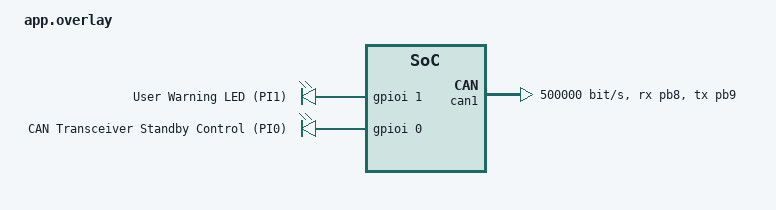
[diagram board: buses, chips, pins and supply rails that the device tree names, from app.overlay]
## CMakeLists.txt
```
# ==============================================================================
# File: zephyr_project/CMakeLists.txt
# Mục đích: File điều phối biên dịch chuẩn của ứng dụng Zephyr RTOS
# ==============================================================================

cmake_minimum_required(VERSION 3.20.0)

# Tìm kiếm và tích hợp hệ điều hành Zephyr RTOS vào dự án
find_package(Zephyr REQUIRED HINTS $ENV{ZEPHYR_BASE})

# Đặt tên định danh cho dự án ô tô
project(automotive_can_gateway_cluster)

# Đăng ký các file mã nguồn C vào target biên dịch
target_sources(app PRIVATE
    src/main.c
    src/can_gateway.c
    src/dbc_decoder.c
    src/safety_monitor.c
    src/diag_shell.c
)
```

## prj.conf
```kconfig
# ==============================================================================
# File: zephyr_project/prj.conf
# Mục đích: Cấu hình tính năng Kconfig cho dự án Automotive CAN Gateway & Cluster
# ==============================================================================

# 1. Bật hệ thống CAN Bus và GPIO điều khiển
CONFIG_CAN=y
CONFIG_CAN_INIT_PRIORITY=80
CONFIG_CAN_MAX_FILTER=5
CONFIG_GPIO=y

# 2. Bật hệ thống Console UART và Ghi Log Bất Đồng Bộ
CONFIG_SERIAL=y
CONFIG_CONSOLE=y
CONFIG_UART_CONSOLE=y
CONFIG_LOG=y
CONFIG_LOG_MODE_DEFERRED=y
CONFIG_LOG_DEFAULT_LEVEL=3

# 3. Khiên bảo vệ tràn ngăn xếp bằng phần cứng MPU Cortex-M7
CONFIG_ARM_MPU=y
CONFIG_HW_STACK_PROTECTION=y
CONFIG_MPU_STACK_GUARD=y

# 4. Giám sát độ đầy Stack và Đặt tên cho các Thread lúc Runtime
CONFIG_THREAD_NAME=y
CONFIG_THREAD_ANALYZER=y
CONFIG_THREAD_ANALYZER_USE_LOG=y
CONFIG_THREAD_ANALYZER_AUTO=y
CONFIG_THREAD_ANALYZER_AUTO_INTERVAL=10

# 5. Giao diện dòng lệnh tương tác chẩn đoán Zephyr Shell CLI
CONFIG_SHELL=y
CONFIG_SHELL_BACKEND_SERIAL=y
CONFIG_SHELL_PROMPT_UART="ecu:~$ "
```

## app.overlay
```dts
/* ==============================================================================
 * File: zephyr_project/app.overlay
 * Mục đích: Ghi đè phần cứng cho bo mạch STM32F746G-Discovery
 * ============================================================================== */

/ {
    aliases {
        can-primary = &can1;
        led-warn = &user_led_1;
    };

    leds {
        compatible = "gpio-leds";
        user_led_1: led_1 {
            gpios = <&gpioi 1 GPIO_ACTIVE_HIGH>;
            label = "User Warning LED (PI1)";
        };
    };

    /* Định nghĩa chân Standby của IC CAN Transceiver ngoài (TJA1050 / SN65HVD230) */
    transceiver {
        compatible = "gpio-leds";
        can_stb: stb_pin {
            gpios = <&gpioi 0 GPIO_ACTIVE_HIGH>;
            label = "CAN Transceiver Standby Control (PI0)";
        };
    };
};

/* Kích hoạt ngoại vi CAN1 (Chân PB8: RX, PB9: TX) */
&can1 {
    pinctrl-0 = <&can1_rx_pb8 &can1_tx_pb9>;
    pinctrl-names = "default";
    status = "okay";
    bitrate = <500000>;
    sample-point = <875>;

    /* Mẹo: Bật thuộc tính 'loopback;' bên dưới nếu muốn tự test trên 1 bo mạch duy nhất */
    /* loopback; */
};
```

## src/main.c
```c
/**
 * ==============================================================================
 * File: zephyr_project/src/main.c
 * Mục đích: Ứng dụng chính Zephyr RTOS (CAN Gateway, DBC/E2E, Multi-threading, Safety Monitor)
 * ==============================================================================
 */

#include <zephyr/kernel.h>
#include <zephyr/drivers/gpio.h>
#include <zephyr/logging/log.h>
#include "can_gateway.h"
#include "dbc_decoder.h"
#include "safety_monitor.h"

LOG_MODULE_REGISTER(main_app, LOG_LEVEL_INF);

/* 1. Biến toàn cục lưu trữ thông số xe hơi, được bảo vệ bằng k_mutex (Priority Inheritance) */
VehicleTelemetry_t g_current_telemetry = { 0 };
K_MUTEX_DEFINE(g_telemetry_mutex);

/* 2. Lấy đèn LED cảnh báo người dùng từ Devicetree (Chân PI1) */
static const struct gpio_dt_spec warn_led = GPIO_DT_SPEC_GET_OR(DT_ALIAS(led_warn), gpios, {0});

/* ==============================================================================
 * LUỒNG 1: CAN INGESTION & DBC DECODER WORKER (Mức ưu tiên 5)
 * ============================================================================== */
#define CAN_WORKER_STACK_SIZE 2048
#define CAN_WORKER_PRIO       5

void can_worker_thread_entry(void *p1, void *p2, void *p3)
{
    ARG_UNUSED(p1); ARG_UNUSED(p2); ARG_UNUSED(p3);

    struct can_frame rx_frame;
    VehicleTelemetry_t local_tel;

    LOG_INF("CAN Worker Thread da khoi dong (Priority = %d).", CAN_WORKER_PRIO);

    while (1) {
        /* Chờ gói tin CAN mới từ hàng đợi (Zero-CPU khi bus rảnh) */
        k_msgq_get(&raw_can_msgq, &rx_frame, K_FOREVER);

        /* Giải mã Vector DBC và xác thực 3 lớp an toàn AUTOSAR E2E */
        if (dbc_decode_vehicle_frame(rx_frame.data, rx_frame.dlc, &local_tel)) {
            /* Cập nhật thông số an toàn đa luồng bằng Mutex */
            k_mutex_lock(&g_telemetry_mutex, K_FOREVER);
            g_current_telemetry = local_tel;
            k_mutex_unlock(&g_telemetry_mutex);

            /* Gửi cập nhật sang hệ thống giám sát sự cố */
            safety_monitor_update(&local_tel);

            LOG_INF("CAN Packet OK: Speed = %u km/h | RPM = %u | Temp = %d C",
                    local_tel.speed_kmh, local_tel.engine_rpm, local_tel.coolant_temp);
        } else {
            LOG_WRN("CAN Frame ID 0x%03X bi loi E2E hoac khong dung dinh dang!", rx_frame.id);
        }
    }
}

K_THREAD_DEFINE(can_worker_tid, CAN_WORKER_STACK_SIZE,
                can_worker_thread_entry, NULL, NULL, NULL,
                CAN_WORKER_PRIO, 0, 0);

/* ==============================================================================
 * LUỒNG 2: SAFETY SUPERVISOR & LED ALERT (Mức ưu tiên 6)
 * ============================================================================== */
#define SAFETY_STACK_SIZE 1024
#define SAFETY_PRIO       6

void safety_thread_entry(void *p1, void *p2, void *p3)
{
    ARG_UNUSED(p1); ARG_UNUSED(p2); ARG_UNUSED(p3);

    if (warn_led.port != NULL && gpio_is_ready_dt(&warn_led)) {
        gpio_pin_configure_dt(&warn_led, GPIO_OUTPUT_INACTIVE);
    }

    LOG_INF("Safety Supervisor Thread da khoi dong (Priority = %d).", SAFETY_PRIO);

    while (1) {
        /* Kiểm tra định kỳ mỗi 200ms */
        k_msleep(200);

        if (safety_monitor_is_fault_active()) {
            /* Nếu có lỗi phát sinh (Timeout mất CAN, Quá nhiệt...) -> Nhấp nháy LED cảnh báo */
            if (warn_led.port != NULL) {
                gpio_pin_toggle_dt(&warn_led);
            }
        } else {
            /* Hệ thống bình thường: Tắt đèn LED */
            if (warn_led.port != NULL) {
                gpio_pin_set_dt(&warn_led, 0);
            }
        }
    }
}

K_THREAD_DEFINE(safety_tid, SAFETY_STACK_SIZE,
                safety_thread_entry, NULL, NULL, NULL,
                SAFETY_PRIO, 0, 0);

/* ==============================================================================
 * LUỒNG CHÍNH (MAIN THREAD)
 * ============================================================================== */
int main(void)
{
    LOG_INF("==================================================");
    LOG_INF("   AUTOMOTIVE SMART CAN GATEWAY & CLUSTER OK!     ");
    LOG_INF("   RTOS Kernel: Zephyr OS on STM32F746 Cortex-M7  ");
    LOG_INF("   Build Time: %s %s", __DATE__, __TIME__);
    LOG_INF("==================================================");

    /* 1. Khởi tạo hệ thống giám sát an toàn */
    safety_monitor_init();

    /* 2. Khởi tạo CAN Subsystem và cấu hình bộ lọc */
    int ret = can_gateway_init();
    if (ret != 0) {
        LOG_ERR("Loi khoi tao CAN Gateway! Ma loi: %d", ret);
        return ret;
    }

    LOG_INF("Go lenh 'help' tren Console UART de xem danh sach lenh chan doan CLI.");
    return 0;
}
```

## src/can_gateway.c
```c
/**
 * ==============================================================================
 * File: zephyr_project/src/can_gateway.c
 * Mục đích: Hiện thực hóa giao tiếp CAN Subsystem, STB Pin và Bus-Off FSM
 * ==============================================================================
 */

#include "can_gateway.h"
#include <zephyr/drivers/gpio.h>
#include <zephyr/logging/log.h>

LOG_MODULE_REGISTER(can_gateway, LOG_LEVEL_INF);

/* 1. Định nghĩa hàng đợi chứa tối đa 16 gói tin CAN */
K_MSGQ_DEFINE(raw_can_msgq, sizeof(struct can_frame), CAN_RX_QUEUE_SIZE, 4);

/* 2. Lấy thiết bị CAN từ Devicetree */
static const struct device *const can_dev = DEVICE_DT_GET(DT_ALIAS(can_primary));

/* 3. Lấy chân STB điều khiển IC Transceiver từ Devicetree */
static const struct gpio_dt_spec stb_spec = GPIO_DT_SPEC_GET_OR(DT_NODELABEL(can_stb), gpios, {0});

/* Callback giám sát máy trạng thái lỗi phần cứng Bus-Off */
static void can_state_change_handler(const struct device *dev, enum can_state state,
                                     struct can_bus_err_cnt err_cnt, void *user_data)
{
    ARG_UNUSED(dev);
    ARG_UNUSED(user_data);

    if (state == CAN_STATE_BUS_OFF) {
        LOG_ERR("CAN ALARM: Phat hien trang thai BUS-OFF! TEC=%d, REC=%d", 
                err_cnt.tx_err_cnt, err_cnt.rx_err_cnt);
        /* Kích hoạt tự động phục hồi an toàn */
#if defined(CONFIG_CAN_MANUAL_RECOVERY_MODE)
        can_recover(can_dev, K_MSEC(100));
#else
        /* Trên STM32 bxCAN, phần cứng tự quản lý Bus-Off (ABOM) hoặc phục hồi bằng stop/start */
        can_stop(can_dev);
        k_msleep(100);
        can_start(can_dev);
#endif
    }
}

int can_gateway_init(void)
{
    int ret;

    /* A. Đánh thức Transceiver: Kéo chân STB xuống mức LOW (0V) */
    if (stb_spec.port != NULL && gpio_is_ready_dt(&stb_spec)) {
        gpio_pin_configure_dt(&stb_spec, GPIO_OUTPUT_INACTIVE);
        gpio_pin_set_dt(&stb_spec, 0);
        LOG_INF("CAN Transceiver da thuc tinh (STB = LOW).");
    }

    /* B. Kiểm tra tính sẵn sàng của bộ điều khiển CAN */
    if (!device_is_ready(can_dev)) {
        LOG_ERR("Loi: Ngoai vi CAN1 chua san sang!");
        return -ENODEV;
    }

    /* C. Đăng ký callback giám sát lỗi Bus-Off */
    can_set_state_change_callback(can_dev, can_state_change_handler, NULL);

    /* D. Bật chế độ Loopback để tự truyền/nhận độc lập trên 1 board mà không cần CAN Transceiver ngoài */
    can_set_mode(can_dev, CAN_MODE_LOOPBACK);

    /* E. Bắt đầu kích hoạt bộ điều khiển CAN */
    ret = can_start(can_dev);
    if (ret != 0) {
        LOG_ERR("Khong the khoi dong CAN controller! Ma loi: %d", ret);
        return ret;
    }

    /* E. Cấu hình bộ lọc phần cứng nhận ID 0x123 (Standard ID) */
    const struct can_filter rx_filter = {
        .id = 0x123,
        .mask = 0x7FF, /* So khớp chính xác ID 0x123 */
        .flags = 0
    };

    /* Gắn trực tiếp bộ lọc phần cứng vào hàng đợi k_msgq (Zero-Lock) */
    ret = can_add_rx_filter_msgq(can_dev, &raw_can_msgq, &rx_filter);
    if (ret < 0) {
        LOG_ERR("Loi dang ky can_add_rx_filter_msgq: %d", ret);
        return ret;
    }

    LOG_INF("CAN Gateway da san sang! Filter ID=0x123 da nap thanh cong.");
    return 0;
}

int can_gateway_send_frame(const struct can_frame *frame)
{
    if (!device_is_ready(can_dev)) return -ENODEV;
    return can_send(can_dev, frame, K_MSEC(100), NULL, NULL);
}
```

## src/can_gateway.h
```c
/**
 * ==============================================================================
 * File: zephyr_project/src/can_gateway.h
 * Mục đích: Giao diện tiếp nhận mạng CAN và hàng đợi k_msgq trong Zephyr
 * ==============================================================================
 */

#ifndef CAN_GATEWAY_H
#define CAN_GATEWAY_H

#include <zephyr/kernel.h>
#include <zephyr/drivers/can.h>

#define CAN_RX_QUEUE_SIZE 16

/* Hàng đợi toàn cục trung chuyển gói tin CAN từ driver ngầm sang Worker Thread */
extern struct k_msgq raw_can_msgq;

/**
 * @brief Khởi tạo ngoại vi CAN1, thức tỉnh Transceiver và gắn filter vào k_msgq
 * @return 0 nếu thành công, mã lỗi âm nếu thất bại
 */
int can_gateway_init(void);

/**
 * @brief Bắn một bản tin CAN ra mạng vật lý
 * @param frame Con trỏ gói tin can_frame
 * @return 0 nếu phát thành công
 */
int can_gateway_send_frame(const struct can_frame *frame);

#endif /* CAN_GATEWAY_H */
```

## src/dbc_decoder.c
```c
/**
 * ==============================================================================
 * File: zephyr_project/src/dbc_decoder.c
 * Mục đích: Cài đặt thuật toán kiểm tra AUTOSAR E2E Profile 1 và giải nén bit DBC
 * ==============================================================================
 */

#include "dbc_decoder.h"
#include <zephyr/logging/log.h>

LOG_MODULE_REGISTER(dbc_decoder, LOG_LEVEL_INF);

/* Thuật toán AUTOSAR E2E CRC-8 (Đa thức SAE J1850 0x2F, Init 0xFF, XOR 0xFF) */
static uint8_t compute_e2e_crc8(const uint8_t *data, uint8_t len, uint16_t data_id)
{
    uint8_t crc = 0xFF;

    /* Nhồi Data ID bí mật vào trước */
    uint8_t id_bytes[2] = { (uint8_t)(data_id & 0xFF), (uint8_t)((data_id >> 8) & 0xFF) };
    for (int i = 0; i < 2; i++) {
        crc ^= id_bytes[i];
        for (int b = 0; b < 8; b++) {
            if (crc & 0x80) {
                crc = (crc << 1) ^ 0x2F;
            } else {
                crc <<= 1;
            }
        }
    }

    /* Tính tiếp qua payload từ Byte 1 đến Byte 7 */
    for (uint8_t i = 0; i < len; i++) {
        crc ^= data[i];
        for (int b = 0; b < 8; b++) {
            if (crc & 0x80) {
                crc = (crc << 1) ^ 0x2F;
            } else {
                crc <<= 1;
            }
        }
    }

    return crc ^ 0xFF;
}

bool dbc_decode_vehicle_frame(const uint8_t *data, uint8_t dlc, VehicleTelemetry_t *out)
{
    if (dlc < 8 || out == NULL) return false;

    static uint8_t last_counter = 0xFF;

    /* 1. KIỂM TRA LỚP 1: E2E CRC-8 */
    uint8_t received_crc = data[0];
    uint8_t expected_crc = compute_e2e_crc8(&data[1], 7, VEHICLE_DATA_ID);

    if (received_crc != expected_crc) {
        LOG_WRN("E2E CANH BAO: Sai ma CRC-8! Nhan: 0x%02X, Tinh: 0x%02X", received_crc, expected_crc);
        out->is_e2e_valid = false;
        return false;
    }

    /* 2. KIỂM TRA LỚP 2: ROLLING COUNTER */
    uint8_t current_counter = data[1] & 0x0F;
    if (last_counter != 0xFF) {
        uint8_t next_counter = (last_counter + 1) % 16;
        if (current_counter != next_counter) {
            LOG_WRN("E2E CANH BAO: Sai Rolling Counter! Hien tai: %d, Mong doi: %d", 
                    current_counter, next_counter);
            out->is_e2e_valid = false;
            return false;
        }
    }
    last_counter = current_counter;
    out->rolling_cnt = current_counter;
    out->is_e2e_valid = true;

    /* 3. GIẢI MÃ TÍN HIỆU VECTOR DBC (TOÁN FIXED-POINT KHÔNG DÙNG FLOAT) */
    /* Signal 1: Tốc độ xe (km/h) tại Byte 2 */
    out->speed_kmh = (uint16_t)data[2];

    /* Signal 2: Vòng tua máy RPM (Byte 3 LSB, Byte 4 MSB, Factor = 0.25 -> chia 4) */
    uint16_t raw_rpm = (uint16_t)data[3] | ((uint16_t)data[4] << 8);
    out->engine_rpm = (raw_rpm >> 2);

    /* Signal 3: Nhiệt độ nước làm mát tại Byte 5 (Factor = 1, Offset = -40) */
    out->coolant_temp = (int16_t)data[5] - 40;

    return true;
}
```

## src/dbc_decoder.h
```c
/**
 * ==============================================================================
 * File: zephyr_project/src/dbc_decoder.h
 * Mục đích: Khai báo giao diện giải mã tín hiệu Vector DBC và AUTOSAR E2E
 * ==============================================================================
 */

#ifndef DBC_DECODER_H
#define DBC_DECODER_H

#include <stdint.h>
#include <stdbool.h>

#define VEHICLE_DATA_ID 0x1A2B /* Data ID bí mật của bản tin xe hơi */

typedef struct {
    uint16_t speed_kmh;     /* Tốc độ xe (0 - 240 km/h) */
    uint16_t engine_rpm;    /* Vòng tua động cơ (0 - 8000 RPM) */
    int16_t  coolant_temp;  /* Nhiệt độ nước làm mát (-40 đến +150 degC) */
    uint8_t  rolling_cnt;   /* Bộ đếm vòng E2E */
    bool     is_e2e_valid;  /* Cờ xác thực toàn vẹn dữ liệu */
} VehicleTelemetry_t;

/**
 * @brief Giải mã gói tin CAN 8-byte, kiểm tra mã AUTOSAR E2E CRC-8 và bóc tách tín hiệu
 * @param data Con trỏ dữ liệu 8 bytes
 * @param dlc Độ dài bản tin
 * @param out Con trỏ lưu trữ thông số sau giải mã
 * @return true nếu giải mã và kiểm tra E2E thành công
 */
bool dbc_decode_vehicle_frame(const uint8_t *data, uint8_t dlc, VehicleTelemetry_t *out);

#endif /* DBC_DECODER_H */
```

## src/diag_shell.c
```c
/**
 * ==============================================================================
 * File: zephyr_project/src/diag_shell.c
 * Mục đích: Giao diện dòng lệnh Zephyr Shell CLI phục vụ chẩn đoán kỹ thuật
 * ==============================================================================
 */

#include <zephyr/kernel.h>
#include <zephyr/shell/shell.h>
#include <stdlib.h>
#include "safety_monitor.h"
#include "can_gateway.h"

extern VehicleTelemetry_t g_current_telemetry;
extern struct k_mutex g_telemetry_mutex;

static int cmd_vehicle_status(const struct shell *sh, size_t argc, char **argv)
{
    ARG_UNUSED(argc);
    ARG_UNUSED(argv);

    k_mutex_lock(&g_telemetry_mutex, K_FOREVER);
    shell_print(sh, "========================================");
    shell_print(sh, "   THONG SO VAN HANH XE HOI (TELEMETRY) ");
    shell_print(sh, "========================================");
    shell_print(sh, "• Toc do hien tai : %u km/h", g_current_telemetry.speed_kmh);
    shell_print(sh, "• Vong tua may    : %u RPM", g_current_telemetry.engine_rpm);
    shell_print(sh, "• Nhiet do nuoc   : %d degC", g_current_telemetry.coolant_temp);
    shell_print(sh, "• Rolling Counter : %u", g_current_telemetry.rolling_cnt);
    shell_print(sh, "• E2E Integrity   : %s", g_current_telemetry.is_e2e_valid ? "VALID (OK)" : "CORRUPT (FAIL)");
    shell_print(sh, "========================================");
    k_mutex_unlock(&g_telemetry_mutex);

    return 0;
}

static int cmd_dtc_read(const struct shell *sh, size_t argc, char **argv)
{
    ARG_UNUSED(argc);
    ARG_UNUSED(argv);

    uint16_t dtcs[8];
    uint8_t count = safety_monitor_get_active_dtc(dtcs, 8);

    shell_print(sh, "Danh sach ma loi chan doan (DTC) hien huu (%u loi):", count);
    if (count == 0) {
        shell_print(sh, "➔ Khong co ma loi nao. He thong AN TOAN tuyet doi.");
    } else {
        for (uint8_t i = 0; i < count; i++) {
            shell_print(sh, " [%u] DTC: 0x%04X", i + 1, dtcs[i]);
        }
    }
    return 0;
}

static int cmd_dtc_clear(const struct shell *sh, size_t argc, char **argv)
{
    ARG_UNUSED(argc);
    ARG_UNUSED(argv);

    safety_monitor_clear_dtc();
    shell_print(sh, "➔ Da xoa toan bo ma loi chan doan thanh cong.");
    return 0;
}

/* --------------------------------------------------------------------------
 * BỘ MÔ PHỎNG PHÁT BẢN TIN CAN XE HƠI (CAN SIMULATOR & INJECTOR)
 * -------------------------------------------------------------------------- */
static bool s_auto_sim = true; /* Mặc định bật tự động để có số liệu xe chạy ngay khi nạp */

static void send_sim_frame(uint16_t speed, uint16_t rpm, int8_t temp, bool corrupt_crc)
{
    static uint8_t sim_counter = 0;
    sim_counter = (sim_counter + 1) % 16;

    uint16_t raw_rpm = rpm * 4;
    uint8_t temp_raw = (uint8_t)(temp + 40);

    struct can_frame sim_frame = {
        .id = 0x123,
        .dlc = 8,
        .data = {
            0, /* Byte 0: CRC */
            sim_counter & 0x0F,
            (uint8_t)speed,
            (uint8_t)(raw_rpm & 0xFF),
            (uint8_t)((raw_rpm >> 8) & 0xFF),
            temp_raw,
            0x00, 0x00
        }
    };

    /* Tính E2E CRC-8 cho payload Byte 1 đến Byte 7 */
    uint8_t crc = 0xFF;
    uint8_t id_bytes[2] = { (uint8_t)(VEHICLE_DATA_ID & 0xFF), (uint8_t)((VEHICLE_DATA_ID >> 8) & 0xFF) };
    for (int i = 0; i < 2; i++) {
        crc ^= id_bytes[i];
        for (int b = 0; b < 8; b++) crc = (crc & 0x80) ? ((crc << 1) ^ 0x2F) : (crc << 1);
    }
    for (int i = 1; i < 8; i++) {
        crc ^= sim_frame.data[i];
        for (int b = 0; b < 8; b++) crc = (crc & 0x80) ? ((crc << 1) ^ 0x2F) : (crc << 1);
    }
    sim_frame.data[0] = corrupt_crc ? (crc ^ 0xAA) : (crc ^ 0xFF);

    can_gateway_send_frame(&sim_frame);
}

/* Luồng phát xe chạy tự động 5Hz (Mỗi 200ms) */
static void sim_thread_entry(void *p1, void *p2, void *p3)
{
    ARG_UNUSED(p1); ARG_UNUSED(p2); ARG_UNUSED(p3);
    uint16_t speed = 50;
    int dir = 1;

    while (1) {
        k_msleep(200);
        if (s_auto_sim) {
            speed += dir * 2;
            if (speed >= 115) dir = -1;
            else if (speed <= 45) dir = 1;

            uint16_t rpm = 1200 + speed * 25; /* RPM: 2325 - 4075 RPM */
            send_sim_frame(speed, rpm, 88, false);
        }
    }
}

K_THREAD_DEFINE(sim_tid, 1024, sim_thread_entry, NULL, NULL, NULL, 7, 0, 0);

/* Lệnh giả lập phát tín hiệu xe hơi thủ công */
static int cmd_can_sim(const struct shell *sh, size_t argc, char **argv)
{
    if (argc < 2) {
        shell_print(sh, "Cu phap: can sim <speed_kmh>");
        return -EINVAL;
    }

    uint16_t speed = (uint16_t)atoi(argv[1]);
    uint16_t rpm = 1200 + speed * 25;
    send_sim_frame(speed, rpm, 88, false);
    shell_print(sh, "➔ Da phat 1 goi tin: Toc do = %u km/h, RPM = %u", speed, rpm);
    return 0;
}

/* Bật / tắt luồng tự động phát */
static int cmd_can_auto(const struct shell *sh, size_t argc, char **argv)
{
    if (argc < 2) {
        shell_print(sh, "Trang thai hien tai: %s. Cu phap: can auto <on|off>", s_auto_sim ? "ON (DANG CHAY)" : "OFF (DA DUNG)");
        return 0;
    }

    if (strcmp(argv[1], "on") == 0) {
        s_auto_sim = true;
        shell_print(sh, "➔ Da BAT mo phong CAN tu dong! Xe dang van hanh tren duong.");
    } else if (strcmp(argv[1], "off") == 0) {
        s_auto_sim = false;
        shell_print(sh, "➔ Da TAT mo phong CAN. Mat tin hieu CAN sau 1s se gay loi DTC_U0100!");
    } else {
        shell_print(sh, "Tham so khong hop le! Dung 'can auto on' hoac 'can auto off'");
    }
    return 0;
}

/* Bơm lỗi cố tình để kiểm tra an toàn AUTOSAR */
static int cmd_can_inject(const struct shell *sh, size_t argc, char **argv)
{
    if (argc < 2) {
        shell_print(sh, "Cu phap: can inject <overheat | overspeed | corrupt>");
        return -EINVAL;
    }

    if (strcmp(argv[1], "overheat") == 0) {
        send_sim_frame(90, 3000, 115, false); /* 115 degC > 105 degC -> DTC_P0115 */
        shell_print(sh, "➔ Da bom loi QUA NHIET (115 degC)! Kiem tra bang 'dtc read'");
    } else if (strcmp(argv[1], "overspeed") == 0) {
        send_sim_frame(140, 6800, 88, false); /* 6800 RPM > 6500 RPM -> DTC_P0219 */
        shell_print(sh, "➔ Da bom loi QUA VONG TUA (6800 RPM)! Kiem tra bang 'dtc read'");
    } else if (strcmp(argv[1], "corrupt") == 0) {
        send_sim_frame(80, 2500, 88, true); /* Sai CRC */
        shell_print(sh, "➔ Da bom goi tin SAI MA CRC-8! Kiem tra bang 'vehicle status'");
    } else {
        shell_print(sh, "Loi khong ho tro: overheat, overspeed, corrupt");
    }
    return 0;
}

/* Đăng ký các nhóm lệnh vào Zephyr Shell */
SHELL_STATIC_SUBCMD_SET_CREATE(sub_vehicle,
    SHELL_CMD(status, NULL, "Hien thi thong so xe hoi truc quan", cmd_vehicle_status),
    SHELL_SUBCMD_SET_END
);
SHELL_CMD_REGISTER(vehicle, &sub_vehicle, "Lenh theo doi xe hoi", NULL);

SHELL_STATIC_SUBCMD_SET_CREATE(sub_dtc,
    SHELL_CMD(read, NULL, "Doc danh sach ma loi chan doan", cmd_dtc_read),
    SHELL_CMD(clear, NULL, "Xoa toan bo ma loi chan doan", cmd_dtc_clear),
    SHELL_SUBCMD_SET_END
);
SHELL_CMD_REGISTER(dtc, &sub_dtc, "Lenh chan doan ma loi", NULL);

SHELL_STATIC_SUBCMD_SET_CREATE(sub_can,
    SHELL_CMD(sim, NULL, "Gia lap phat 1 goi tin CAN (can sim <speed>)", cmd_can_sim),
    SHELL_CMD(auto, NULL, "Bat/tat mo phong xe chay tu dong (can auto <on|off>)", cmd_can_auto),
    SHELL_CMD(inject, NULL, "Bom loi an toan (can inject <overheat|overspeed|corrupt>)", cmd_can_inject),
    SHELL_SUBCMD_SET_END
);
SHELL_CMD_REGISTER(can, &sub_can, "Lenh mo phong mang CAN", NULL);
```

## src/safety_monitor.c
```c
/**
 * ==============================================================================
 * File: zephyr_project/src/safety_monitor.c
 * Mục đích: Hiện thực hóa máy trạng thái giám sát an toàn và quản lý DTC
 * ==============================================================================
 */

#include "safety_monitor.h"
#include <zephyr/kernel.h>
#include <zephyr/logging/log.h>

LOG_MODULE_REGISTER(safety_monitor, LOG_LEVEL_INF);

static K_MUTEX_DEFINE(s_dtc_mutex);
static uint16_t s_active_dtcs[8];
static uint8_t  s_dtc_count = 0;
static uint32_t s_last_msg_time = 0;

static void add_dtc_internal(uint16_t dtc)
{
    for (uint8_t i = 0; i < s_dtc_count; i++) {
        if (s_active_dtcs[i] == dtc) return; /* Đã tồn tại */
    }
    if (s_dtc_count < 8) {
        s_active_dtcs[s_dtc_count++] = dtc;
        LOG_ERR("DTC ALARM: Phat sinh ma loi moi: 0x%04X!", dtc);
    }
}

void safety_monitor_init(void)
{
    s_dtc_count = 0;
    s_last_msg_time = k_uptime_get_32();
}

void safety_monitor_update(const VehicleTelemetry_t *tel)
{
    k_mutex_lock(&s_dtc_mutex, K_FOREVER);

    s_last_msg_time = k_uptime_get_32();

    /* Kiểm tra quá nhiệt */
    if (tel->coolant_temp > 105) {
        add_dtc_internal(DTC_P0115);
    }

    /* Kiểm tra quá vòng tua */
    if (tel->engine_rpm > 6500) {
        add_dtc_internal(DTC_P0219);
    }

    k_mutex_unlock(&s_dtc_mutex);
}

uint8_t safety_monitor_get_active_dtc(uint16_t *dtc_list, uint8_t max_count)
{
    k_mutex_lock(&s_dtc_mutex, K_FOREVER);

    /* Rà soát lỗi mất kết nối CAN quá 1000ms */
    if ((uint32_t)(k_uptime_get_32() - s_last_msg_time) > 1000) {
        add_dtc_internal(DTC_U0100);
    }

    uint8_t count = (s_dtc_count < max_count) ? s_dtc_count : max_count;
    for (uint8_t i = 0; i < count; i++) {
        dtc_list[i] = s_active_dtcs[i];
    }

    k_mutex_unlock(&s_dtc_mutex);
    return count;
}

void safety_monitor_clear_dtc(void)
{
    k_mutex_lock(&s_dtc_mutex, K_FOREVER);
    s_dtc_count = 0;
    s_last_msg_time = k_uptime_get_32();
    LOG_INF("DTC Reset: Toan bo ma loi chan doan da duoc xoa sach.");
    k_mutex_unlock(&s_dtc_mutex);
}

bool safety_monitor_is_fault_active(void)
{
    k_mutex_lock(&s_dtc_mutex, K_FOREVER);
    bool active = (s_dtc_count > 0);
    k_mutex_unlock(&s_dtc_mutex);
    return active;
}
```

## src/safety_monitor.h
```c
/**
 * ==============================================================================
 * File: zephyr_project/src/safety_monitor.h
 * Mục đích: Quản lý giám sát an toàn, Timeout và bảng mã lỗi chẩn đoán DTC
 * ==============================================================================
 */

#ifndef SAFETY_MONITOR_H
#define SAFETY_MONITOR_H

#include "dbc_decoder.h"
#include <stdint.h>
#include <stdbool.h>

/* Bảng mã lỗi chẩn đoán chuẩn ô tô (Standard DTCs) */
#define DTC_U0100 0x0100 /* Mất kết nối CAN quá 1000ms (Lost Communication) */
#define DTC_P0115 0x0115 /* Quá nhiệt động cơ > 105 degC (Engine Coolant Overheat) */
#define DTC_P0219 0x0219 /* Quá vòng tua máy > 6500 RPM (Engine Overspeed) */

void safety_monitor_init(void);

/**
 * @brief Cập nhật thông số xe hơi và rà soát ngưỡng an toàn
 * @param tel Con trỏ dữ liệu xe sau giải mã
 */
void safety_monitor_update(const VehicleTelemetry_t *tel);

/**
 * @brief Đọc danh sách các mã lỗi DTC đang kích hoạt
 * @param dtc_list Mảng chứa mã lỗi trả về
 * @param max_count Số lượng tối đa
 * @return Số lượng mã lỗi hiện hữu
 */
uint8_t safety_monitor_get_active_dtc(uint16_t *dtc_list, uint8_t max_count);

/**
 * @brief Xóa toàn bộ mã lỗi chẩn đoán (DTC Clear)
 */
void safety_monitor_clear_dtc(void);

/**
 * @brief Kiểm tra xem hệ thống có đang ở trạng thái báo động không
 * @return true nếu có ít nhất 1 mã lỗi chưa xóa
 */
bool safety_monitor_is_fault_active(void);

#endif /* SAFETY_MONITOR_H */
```
